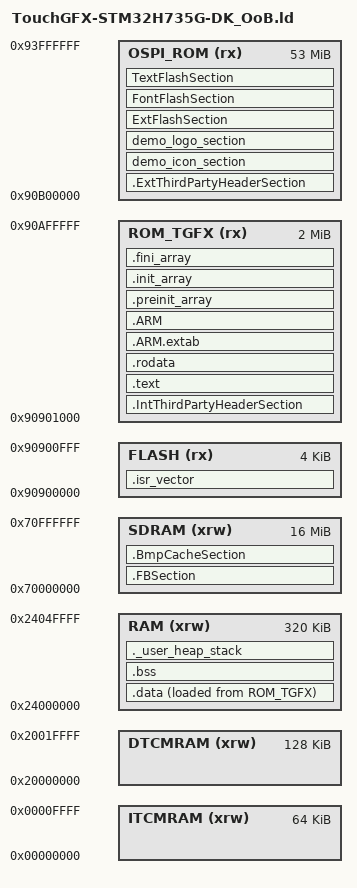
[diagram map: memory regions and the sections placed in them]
/**
 ******************************************************************************
 * @file      LinkerScript.ld
 * @author    Auto-generated by STM32CubeIDE
 * @brief     Linker script for STM32H735IGKx Device from STM32H7 series
 *                      54272Kbytes OSPI_ROM
 *                      2048Kbytes ROM_TGFX
 *                      128Kbytes DTCMRAM
 *                      64Kbytes ITCMRAM
 *                      320Kbytes RAM
 *                      16384Kbytes SDRAM
 *
 *            Set heap size, stack size and stack location according
 *            to application requirements.
 *
 *            Set memory bank area and size if external memory is used
 ******************************************************************************
 * @attention
 *
 * Copyright (c) 2020 STMicroelectronics.
 * All rights reserved.
 *
 * This software is licensed under terms that can be found in the LICENSE file
 * in the root directory of this software component.
 * If no LICENSE file comes with this software, it is provided AS-IS.
 *
 ******************************************************************************
 */

/* Entry Point */
ENTRY(Reset_Handler)

/* Highest address of the user mode stack */
_estack = ORIGIN(RAM) + LENGTH(RAM);	/* end of "RAM" Ram type memory */

_Min_Heap_Size = 0x1000;	/* required amount of heap  */
_Min_Stack_Size = 0x1000;	/* required amount of stack */

/* Memories definition */
MEMORY
{
  DTCMRAM    (xrw)    : ORIGIN = 0x20000000,   LENGTH = 128K
  ITCMRAM    (xrw)    : ORIGIN = 0x00000000,   LENGTH = 64K
  RAM    (xrw)    : ORIGIN = 0x24000000,   LENGTH = 320K
  SDRAM    (xrw)    : ORIGIN = 0x70000000,   LENGTH = 16384K
  OSPI_ROM    (rx)    : ORIGIN = 0x90B00000,   LENGTH = 54272K
  FLASH (rx)             : ORIGIN = 0x90900000, LENGTH = 4K
  ROM_TGFX    (rx)    : ORIGIN = 0x90901000,   LENGTH = 2044K
}

/* Sections */
SECTIONS
{
  /* The startup code into "FLASH" Rom type memory */
  .isr_vector :
  {
    . = ALIGN(4);
    KEEP(*(.isr_vector)) /* Startup code */
    . = ALIGN(4);
  } >FLASH
  
   .IntThirdPartyHeaderSection  : 
  { 
  *(.IntThirdPartyHeaderSection )
  
   } >ROM_TGFX
  

  /* The program code and other data into "ROM_TGFX" Rom type memory */
  .text :
  {
    . = ALIGN(4);
    *(.text)           /* .text sections (code) */
    *(.text*)          /* .text* sections (code) */
    *(.glue_7)         /* glue arm to thumb code */
    *(.glue_7t)        /* glue thumb to arm code */
    *(.eh_frame)

    KEEP (*(.init))
    KEEP (*(.fini))

    . = ALIGN(4);
    _etext = .;        /* define a global symbols at end of code */
  } >ROM_TGFX

  /* Constant data into "ROM_TGFX" Rom type memory */
  .rodata :
  {
    . = ALIGN(4);
    *(.rodata)         /* .rodata sections (constants, strings, etc.) */
    *(.rodata*)        /* .rodata* sections (constants, strings, etc.) */
    . = ALIGN(4);
  } >ROM_TGFX

  .ARM.extab   : { 
    . = ALIGN(4);
    *(.ARM.extab* .gnu.linkonce.armextab.*)
    . = ALIGN(4);
  } >ROM_TGFX
  
  .ARM : {
    . = ALIGN(4);
    __exidx_start = .;
    *(.ARM.exidx*)
    __exidx_end = .;
    . = ALIGN(4);
  } >ROM_TGFX

  .preinit_array     :
  {
    . = ALIGN(4);
    PROVIDE_HIDDEN (__preinit_array_start = .);
    KEEP (*(.preinit_array*))
    PROVIDE_HIDDEN (__preinit_array_end = .);
    . = ALIGN(4);
  } >ROM_TGFX
  
  .init_array :
  {
    . = ALIGN(4);
    PROVIDE_HIDDEN (__init_array_start = .);
    KEEP (*(SORT(.init_array.*)))
    KEEP (*(.init_array*))
    PROVIDE_HIDDEN (__init_array_end = .);
    . = ALIGN(4);
  } >ROM_TGFX
  
  .fini_array :
  {
    . = ALIGN(4);
    PROVIDE_HIDDEN (__fini_array_start = .);
    KEEP (*(SORT(.fini_array.*)))
    KEEP (*(.fini_array*))
    PROVIDE_HIDDEN (__fini_array_end = .);
    . = ALIGN(4);
  } >ROM_TGFX

  /* Used by the startup to initialize data */
  _sidata = LOADADDR(.data);

  /* Initialized data sections into "RAM" Ram type memory */
  .data : 
  {
    . = ALIGN(4);
    _sdata = .;        /* create a global symbol at data start */
    *(.data)           /* .data sections */
    *(.data*)          /* .data* sections */

    . = ALIGN(4);
    _edata = .;        /* define a global symbol at data end */
    
  } >RAM AT> ROM_TGFX

  /* Uninitialized data section into "RAM" Ram type memory */
  . = ALIGN(4);
  .bss :
  {
    /* This is used by the startup in order to initialize the .bss section */
    _sbss = .;         /* define a global symbol at bss start */
    __bss_start__ = _sbss;
    *(.bss)
    *(.bss*)
    *(COMMON)

    . = ALIGN(4);
    _ebss = .;         /* define a global symbol at bss end */
    __bss_end__ = _ebss;
  } >RAM

  /* User_heap_stack section, used to check that there is enough "RAM" Ram  type memory left */
  ._user_heap_stack :
  {
    . = ALIGN(8);
    PROVIDE ( end = . );
    PROVIDE ( _end = . );
    . = . + _Min_Heap_Size;
    . = . + _Min_Stack_Size;
    . = ALIGN(8);
  } >RAM
  
  .ExtThirdPartyHeaderSection : 
  { 
  *(.ExtThirdPartyHeaderSection)
  } >OSPI_ROM  

 demo_icon_section :
  {
  . = ALIGN(8);
  _sdemo_icon_section = .;
  _edemo_icon_section = .; 
   } > OSPI_ROM 
   
 demo_logo_section :
  {
  . = ALIGN(8);
  _sdemo_icon_section = .;
  _edemo_icon_section = .;
   } > OSPI_ROM 

  /* Remove information from the compiler libraries */
  /DISCARD/ :
  {
    libc.a ( * )
    libm.a ( * )
    libgcc.a ( * )
  }
  


  .ARM.attributes 0 : { *(.ARM.attributes) }
  .FBSection (NOLOAD) : { *(.FBSection) } >SDRAM
  .BmpCacheSection(NOLOAD) : { *(.BmpCacheSection) } >SDRAM
   ExtFlashSection  : { *(ExtFlashSection) } >OSPI_ROM
   FontFlashSection  : { *(FontFlashSection) } >OSPI_ROM
   TextFlashSection  : { *(TextFlashSection) } >OSPI_ROM
   
  
  
}
